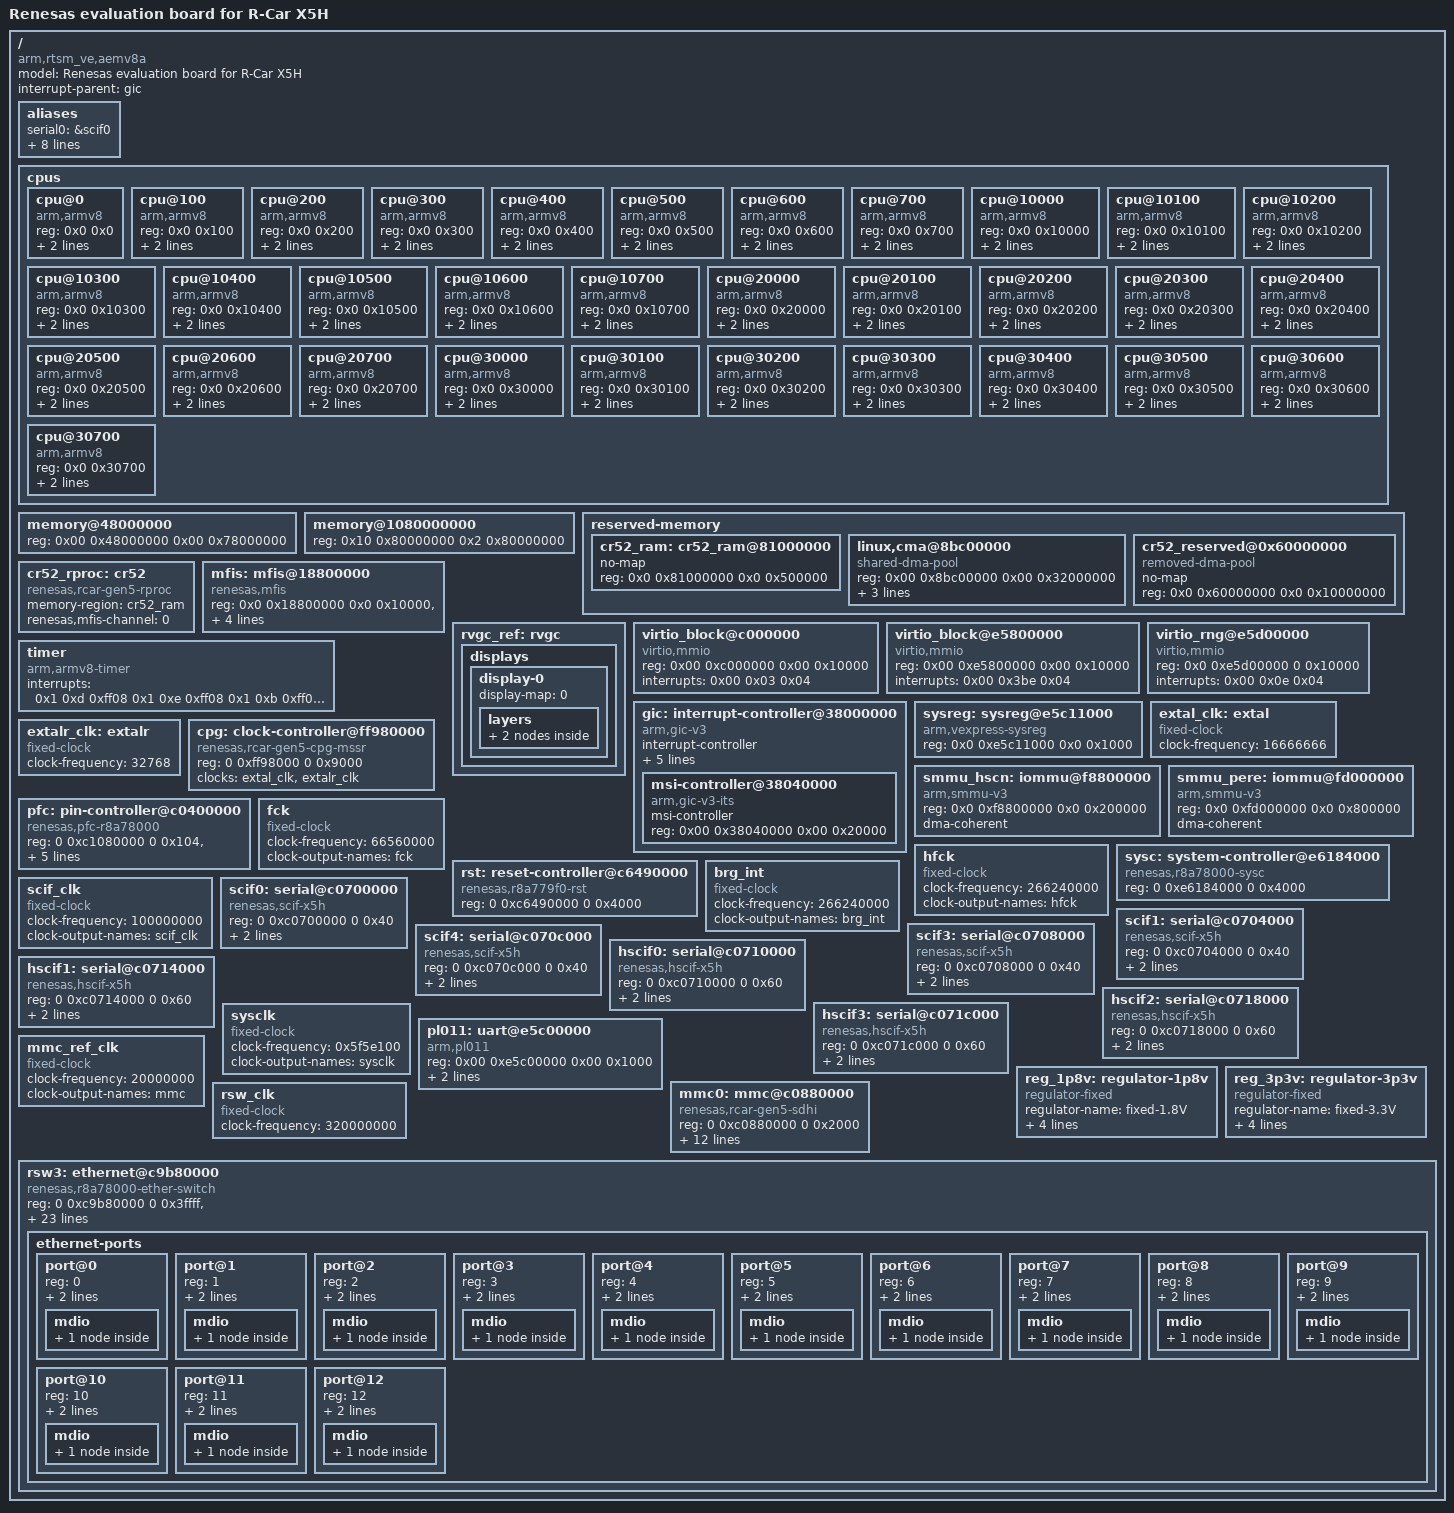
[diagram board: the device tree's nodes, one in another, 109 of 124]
/dts-v1/;

/ {
	model = "Renesas evaluation board for R-Car X5H";
	compatible = "arm,rtsm_ve,aemv8a", "arm,vexpress";
	#address-cells = <2>;
	#size-cells = <2>;

	interrupt-parent = <&gic>;

	aliases {
		serial0 = &scif0;
		serial1 = &scif1;
		serial2 = &scif3;
		serial3 = &scif4;
		serial4 = &hscif0;
		serial5 = &hscif1;
		serial6 = &hscif2;
		serial7 = &hscif3;
		serial8 = &pl011;
	};

	cpus {
		#address-cells = <2>;
		#size-cells = <0>;
		
		cpu@0 {
			device_type = "cpu";
			compatible = "arm,armv8";
			reg = <0x0 0x0>;
			enable-method = "spin-table";
			cpu-release-addr = <0x0 0x7ffff00>;
		};
		cpu@100 {
			device_type = "cpu";
			compatible = "arm,armv8";
			reg = <0x0 0x100>;
			enable-method = "spin-table";
			cpu-release-addr = <0x0 0x7ffff00>;
		};
		cpu@200 {
			device_type = "cpu";
			compatible = "arm,armv8";
			reg = <0x0 0x200>;
			enable-method = "spin-table";
			cpu-release-addr = <0x0 0x7ffff00>;
		};
		cpu@300 {
			device_type = "cpu";
			compatible = "arm,armv8";
			reg = <0x0 0x300>;
			enable-method = "spin-table";
			cpu-release-addr = <0x0 0x7ffff00>;
		};
		cpu@400 {
			device_type = "cpu";
			compatible = "arm,armv8";
			reg = <0x0 0x400>;
			enable-method = "spin-table";
			cpu-release-addr = <0x0 0x7ffff00>;
		};
		cpu@500 {
			device_type = "cpu";
			compatible = "arm,armv8";
			reg = <0x0 0x500>;
			enable-method = "spin-table";
			cpu-release-addr = <0x0 0x7ffff00>;
		};
		cpu@600 {
			device_type = "cpu";
			compatible = "arm,armv8";
			reg = <0x0 0x600>;
			enable-method = "spin-table";
			cpu-release-addr = <0x0 0x7ffff00>;
		};
		cpu@700 {
			device_type = "cpu";
			compatible = "arm,armv8";
			reg = <0x0 0x700>;
			enable-method = "spin-table";
			cpu-release-addr = <0x0 0x7ffff00>;
		};
		cpu@10000 {
			device_type = "cpu";
			compatible = "arm,armv8";
			reg = <0x0 0x10000>;
			enable-method = "spin-table";
			cpu-release-addr = <0x0 0x7ffff00>;
		};
		cpu@10100 {
			device_type = "cpu";
			compatible = "arm,armv8";
			reg = <0x0 0x10100>;
			enable-method = "spin-table";
			cpu-release-addr = <0x0 0x7ffff00>;
		};
		cpu@10200 {
			device_type = "cpu";
			compatible = "arm,armv8";
			reg = <0x0 0x10200>;
			enable-method = "spin-table";
			cpu-release-addr = <0x0 0x7ffff00>;
		};
		cpu@10300 {
			device_type = "cpu";
			compatible = "arm,armv8";
			reg = <0x0 0x10300>;
			enable-method = "spin-table";
			cpu-release-addr = <0x0 0x7ffff00>;
		};
		cpu@10400 {
			device_type = "cpu";
			compatible = "arm,armv8";
			reg = <0x0 0x10400>;
			enable-method = "spin-table";
			cpu-release-addr = <0x0 0x7ffff00>;
		};
		cpu@10500 {
			device_type = "cpu";
			compatible = "arm,armv8";
			reg = <0x0 0x10500>;
			enable-method = "spin-table";
			cpu-release-addr = <0x0 0x7ffff00>;
		};
		cpu@10600 {
			device_type = "cpu";
			compatible = "arm,armv8";
			reg = <0x0 0x10600>;
			enable-method = "spin-table";
			cpu-release-addr = <0x0 0x7ffff00>;
		};
		cpu@10700 {
			device_type = "cpu";
			compatible = "arm,armv8";
			reg = <0x0 0x10700>;
			enable-method = "spin-table";
			cpu-release-addr = <0x0 0x7ffff00>;
		};
		cpu@20000 {
			device_type = "cpu";
			compatible = "arm,armv8";
			reg = <0x0 0x20000>;
			enable-method = "spin-table";
			cpu-release-addr = <0x0 0x7ffff00>;
		};
		cpu@20100 {
			device_type = "cpu";
			compatible = "arm,armv8";
			reg = <0x0 0x20100>;
			enable-method = "spin-table";
			cpu-release-addr = <0x0 0x7ffff00>;
		};
		cpu@20200 {
			device_type = "cpu";
			compatible = "arm,armv8";
			reg = <0x0 0x20200>;
			enable-method = "spin-table";
			cpu-release-addr = <0x0 0x7ffff00>;
		};
		cpu@20300 {
			device_type = "cpu";
			compatible = "arm,armv8";
			reg = <0x0 0x20300>;
			enable-method = "spin-table";
			cpu-release-addr = <0x0 0x7ffff00>;
		};
		cpu@20400 {
			device_type = "cpu";
			compatible = "arm,armv8";
			reg = <0x0 0x20400>;
			enable-method = "spin-table";
			cpu-release-addr = <0x0 0x7ffff00>;
		};
		cpu@20500 {
			device_type = "cpu";
			compatible = "arm,armv8";
			reg = <0x0 0x20500>;
			enable-method = "spin-table";
			cpu-release-addr = <0x0 0x7ffff00>;
		};
		cpu@20600 {
			device_type = "cpu";
			compatible = "arm,armv8";
			reg = <0x0 0x20600>;
			enable-method = "spin-table";
			cpu-release-addr = <0x0 0x7ffff00>;
		};
		cpu@20700 {
			device_type = "cpu";
			compatible = "arm,armv8";
			reg = <0x0 0x20700>;
			enable-method = "spin-table";
			cpu-release-addr = <0x0 0x7ffff00>;
		};
		cpu@30000 {
			device_type = "cpu";
			compatible = "arm,armv8";
			reg = <0x0 0x30000>;
			enable-method = "spin-table";
			cpu-release-addr = <0x0 0x7ffff00>;
		};
		cpu@30100 {
			device_type = "cpu";
			compatible = "arm,armv8";
			reg = <0x0 0x30100>;
			enable-method = "spin-table";
			cpu-release-addr = <0x0 0x7ffff00>;
		};
		cpu@30200 {
			device_type = "cpu";
			compatible = "arm,armv8";
			reg = <0x0 0x30200>;
			enable-method = "spin-table";
			cpu-release-addr = <0x0 0x7ffff00>;
		};
		cpu@30300 {
			device_type = "cpu";
			compatible = "arm,armv8";
			reg = <0x0 0x30300>;
			enable-method = "spin-table";
			cpu-release-addr = <0x0 0x7ffff00>;
		};
		cpu@30400 {
			device_type = "cpu";
			compatible = "arm,armv8";
			reg = <0x0 0x30400>;
			enable-method = "spin-table";
			cpu-release-addr = <0x0 0x7ffff00>;
		};
		cpu@30500 {
			device_type = "cpu";
			compatible = "arm,armv8";
			reg = <0x0 0x30500>;
			enable-method = "spin-table";
			cpu-release-addr = <0x0 0x7ffff00>;
		};
		cpu@30600 {
			device_type = "cpu";
			compatible = "arm,armv8";
			reg = <0x0 0x30600>;
			enable-method = "spin-table";
			cpu-release-addr = <0x0 0x7ffff00>;
		};
		cpu@30700 {
			device_type = "cpu";
			compatible = "arm,armv8";
			reg = <0x0 0x30700>;
			enable-method = "spin-table";
			cpu-release-addr = <0x0 0x7ffff00>;
		};
	};

	memory@48000000 {
		device_type = "memory";
		reg = <0x00 0x48000000 0x00 0x78000000>;
	};

	memory@1080000000 {
		device_type = "memory";
		reg = <0x10 0x80000000 0x2 0x80000000>;
	};

	reserved-memory {
		#address-cells = <2>;
		#size-cells = <2>;
		ranges;
 
		cr52_ram: cr52_ram@81000000 {
			no-map;
			reg = <0x0 0x81000000 0x0 0x500000>;
		};

		linux,cma@8bc00000 {
			compatible = "shared-dma-pool";
			reg = <0x00 0x8bc00000 0x00 0x32000000>;
			linux;
			reusable;
			linux,cma-default;
		};

		cr52_reserved@0x60000000 {
			compatible = "removed-dma-pool";
			no-map;
			reg = <0x0 0x60000000 0x0 0x10000000>;
		};
	};

	cr52_rproc: cr52 {
		compatible = "renesas,rcar-gen5-rproc";
		memory-region = <&cr52_ram>;
		renesas,mfis-channel = <0>;
	};

	mfis: mfis@18800000 {
		compatible = "renesas,mfis";
		reg = <0x0 0x18800000 0x0 0x10000>, <0x0 0x189e0900 0x0 0x4>;
		reg-names = "io_base", "unlock_reg";
		interrupts = <0 101 4>, <0 103 4>, <0 105 4>, <0 107 4>, <0 109 4>, <0 111 4>, <0 113 4>, <0 115 4>;
		interrupt-names = "eicr0", "eicr1", "eicr2", "eicr3", "eicr4", "eicr5", "eicr6", "eicr7";
		renesas,mfis-channels = <0 1 2 3>;
		status = "okay";
	};

	rvgc_ref: rvgc {
		#address-cells = <2>;
		#size-cells = <2>;
		displays {
			display-0 {
				display-map = <0>;
				layers {
					primary{
						/* Position the layer */
						layer-map=<0x1>;
						size-w=<1920>;
						size-h=<1080>;
						pos-x=<0>;	
						pos-y=<0>;	
						pos-override;
 					};
					overlay-0 {
						layer-map = <0x2>;
						size-w = <1920>;
						size-h = <1080>;
						pos-x = <0>;
						pos-y = <0>;
					};								
				};
			};
		};
	};

	virtio_block@c000000 {
		compatible = "virtio,mmio";
		reg = <0x00 0xc000000 0x00 0x10000>;
		interrupts = <0x00 0x03 0x04>;
		status = "okay";
	};

	virtio_block@e5800000 {
		compatible = "virtio,mmio";
		reg = <0x00 0xe5800000 0x00 0x10000>;
		interrupts = <0x00 0x3be 0x04>;
		status = "okay";
	};

	virtio_rng@e5d00000 {
		compatible = "virtio,mmio";
		reg = <0x0 0xe5d00000 0 0x10000>;
		interrupts = <0x00 0x0e 0x04>;
	};

	timer {
		compatible = "arm,armv8-timer";
		interrupts = <0x1 0xd 0xff08 0x1 0xe 0xff08 0x1 0xb 0xff08 0x1 0xa 0xff08>;
	};

	gic: interrupt-controller@38000000 {
		compatible = "arm,gic-v3";
		#interrupt-cells = <0x03>;
		#address-cells = <0x02>;
		#size-cells = <0x02>;
		ranges;
		interrupt-controller;
		reg = <0x0 0x38000000 0x0 0x10000>, <0x0 0x38080000 0x0 0x4080000>, <0x0 0x0 0x0 0x2000>, <0x0 0x10000 0x0 0x2000>, <0x0 0x20000 0x0 0x2000>;
		interrupts = <0x01 0x09 0xff04>;
		phandle = <0x14>;

		msi-controller@38040000 {
			compatible = "arm,gic-v3-its";
			msi-controller;
			#msi-cells = <0x01>;
			reg = <0x00 0x38040000 0x00 0x20000>;
			phandle = <0x2f>;
		};
	};

	sysreg: sysreg@e5c11000 {
		compatible = "arm,vexpress-sysreg";
		reg = <0x0 0xe5c11000 0x0 0x1000>;
	};

	extal_clk: extal {
		compatible = "fixed-clock";
		#clock-cells = <0>;
		/* This value must be overridden by the board */
		clock-frequency = <16666666>;
	};
	
	extalr_clk: extalr {
		compatible = "fixed-clock";
		#clock-cells = <0>;
		/* This value must be overridden by the board */
		clock-frequency = <32768>;
	};
	
	cpg: clock-controller@ff980000 {
		compatible = "renesas,rcar-gen5-cpg-mssr";
		reg = <0 0xff98000 0 0x9000>;
		clocks = <&extal_clk>, <&extalr_clk>;
		clock-names = "extal", "extalr";
		#clock-cells = <2>;
		#power-domain-cells = <0>;
		#reset-cells = <1>;
	};
	
	smmu_hscn: iommu@f8800000 {
		compatible = "arm,smmu-v3";
		reg = <0x0 0xf8800000 0x0 0x200000>;
		#iommu-cells = <1>;
		dma-coherent;
	};

	smmu_pere: iommu@fd000000 {
		compatible = "arm,smmu-v3";
		reg = <0x0 0xfd000000 0x0 0x800000>;
		#iommu-cells = <1>;
		dma-coherent;
	};

	/* pfc_gen5.dts.txt */
	pfc: pin-controller@c0400000 {
		compatible = "renesas,pfc-r8a78000";
		reg = <0 0xc1080000 0 0x104>,
			  <0 0xc1080800 0 0x104>,
			  <0 0xc1081000 0 0x104>,
			  <0 0xc0800000 0 0x104>,
			  <0 0xc0800800 0 0x104>,
			  <0 0xc0400000 0 0x104>,
			  <0 0xc0400800 0 0x104>,
			  <0 0xc0401000 0 0x104>,
			  <0 0xc0401800 0 0x104>,
			  <0 0xc9b00000 0 0x104>,
			  <0 0xc9b00800 0 0x104>;
	};
	/* pfc_gen5.dts.txt end */

	fck: fck {
		compatible = "fixed-clock";
		#clock-cells = <0>;
		clock-frequency = <66560000>;
		clock-output-names = "fck";
	};
	
	hfck: hfck {
		compatible = "fixed-clock";
		#clock-cells = <0>;
		clock-frequency = <266240000>;
		clock-output-names = "hfck";
	};

	sysc: system-controller@e6184000 {
		compatible = "renesas,r8a78000-sysc";
		reg = <0 0xe6184000 0 0x4000>;
		#power-domain-cells = <1>;
	};

	rst: reset-controller@c6490000 {
		compatible = "renesas,r8a779f0-rst";
		reg = <0 0xc6490000 0 0x4000>;
	};
	
	brg_int: brg_int {
		compatible = "fixed-clock";
		#clock-cells = <0>;
		clock-frequency = <266240000>;
		clock-output-names = "brg_int";
	};
	
	scif_clk: scif_clk {
		compatible = "fixed-clock";
		#clock-cells = <0>;
		clock-frequency = <100000000>;
		clock-output-names = "scif_clk";
	};

	scif0: serial@c0700000 {
		compatible = "renesas,scif-x5h", "renesas,rcar-gen5-scif", "renesas,scif";
		reg = <0 0xc0700000 0 0x40>;
		interrupts = <0 433 4>;
		clocks = <&scif_clk>, <&scif_clk>, <&scif_clk>;
		clock-names = "fck", "brg_int", "scif_clk";
	};

	scif1: serial@c0704000 {
		compatible = "renesas,scif-x5h", "renesas,rcar-gen5-scif", "renesas,scif";
		reg = <0 0xc0704000 0 0x40>;
		interrupts = <0 433 4>;
		clocks = <&scif_clk>, <&scif_clk>, <&scif_clk>;
		clock-names = "fck", "brg_int", "scif_clk";
	};

	scif3: serial@c0708000 {
		compatible = "renesas,scif-x5h", "renesas,rcar-gen5-scif", "renesas,scif";
		reg = <0 0xc0708000 0 0x40>;
		interrupts = <0 433 4>;
		clocks = <&scif_clk>, <&scif_clk>, <&scif_clk>;
		clock-names = "fck", "brg_int", "scif_clk";
	};

	scif4: serial@c070c000 {
		compatible = "renesas,scif-x5h", "renesas,rcar-gen5-scif", "renesas,scif";
		reg = <0 0xc070c000 0 0x40>;
		interrupts = <0 433 4>;
		clocks = <&scif_clk>, <&scif_clk>, <&scif_clk>;
		clock-names = "fck", "brg_int", "scif_clk";
	};

	hscif0: serial@c0710000 {
		compatible = "renesas,hscif-x5h", "renesas,rcar-gen5-hscif", "renesas,hscif";
		reg = <0 0xc0710000 0 0x60>;
		interrupts = <0 434 4>;
		clocks = <&scif_clk>, <&scif_clk>, <&scif_clk>;
		clock-names = "fck", "brg_int", "scif_clk";
	};

	hscif1: serial@c0714000 {
		compatible = "renesas,hscif-x5h", "renesas,rcar-gen5-hscif", "renesas,hscif";
		reg = <0 0xc0714000 0 0x60>;
		interrupts = <0 434 4>;
		clocks = <&scif_clk>, <&scif_clk>, <&scif_clk>;
		clock-names = "fck", "brg_int", "scif_clk";
	};

	hscif2: serial@c0718000 {
		compatible = "renesas,hscif-x5h", "renesas,rcar-gen5-hscif", "renesas,hscif";
		reg = <0 0xc0718000 0 0x60>;
		interrupts = <0 434 4>;
		clocks = <&scif_clk>, <&scif_clk>, <&scif_clk>;
		clock-names = "fck", "brg_int", "scif_clk";
	};

	hscif3: serial@c071c000 {
		compatible = "renesas,hscif-x5h", "renesas,rcar-gen5-hscif", "renesas,hscif";
		reg = <0 0xc071c000 0 0x60>;
		interrupts = <0 434 4>;
		clocks = <&scif_clk>, <&scif_clk>, <&scif_clk>;
		clock-names = "fck", "brg_int", "scif_clk";
	};

	sysclk: sysclk {
		compatible = "fixed-clock";
		#clock-cells = <0x00>;
		clock-frequency = <0x5f5e100>;
		clock-output-names = "sysclk";
	};

	pl011: uart@e5c00000 {
		compatible = "arm,pl011", "arm,primecell";
		reg = <0x00 0xe5c00000 0x00 0x1000>;
		interrupts = <0 13 4>;
		clock-names = "uartclk", "apb_pclk";
		clocks = <&sysclk>, <&sysclk>;
	};

	reg_1p8v: regulator-1p8v {
		compatible = "regulator-fixed";
		regulator-name = "fixed-1.8V";
		regulator-min-microvolt = <1800000>;
		regulator-max-microvolt = <1800000>;
		regulator-boot-on;
		regulator-always-on;
	};

	reg_3p3v: regulator-3p3v {
		compatible = "regulator-fixed";
		regulator-name = "fixed-3.3V";
		regulator-min-microvolt = <3300000>;
		regulator-max-microvolt = <3300000>;
		regulator-boot-on;
		regulator-always-on;
	};

	mmc_ref_clk: mmc_ref_clk {
		compatible = "fixed-clock";
		#clock-cells = <0>;
		clock-frequency = <20000000>;
		clock-output-names = "mmc";
	};

	mmc0: mmc@c0880000 {
		compatible = "renesas,rcar-gen5-sdhi";
		reg = <0 0xc0880000 0 0x2000>;
		interrupts = <0 894 4>;
		clocks = <&mmc_ref_clk>;
		max-frequency = <200000000>;
		vmmc-supply = <&reg_3p3v>;
		vqmmc-supply = <&reg_1p8v>;
		mmc-hs200-1_8v;
		mmc-hs400-1_8v;
		bus-width = <8>;
		no-sd;
		no-sdio;
		non-removable;
		full-pwr-cycle-in-suspend;
	};

	rsw_clk: rsw_clk {
		compatible = "fixed-clock";
		clock-frequency = <320000000>;
		#clock-cells = <0>;
	};

	rsw3: ethernet@c9b80000 {
		compatible = "renesas,r8a78000-ether-switch",
					"renesas,etherswitch";
		reg =	<0 0xc9b80000 0 0x3ffff>,
			<0 0xc9c89000 0 0x7ff>,
			<0 0xc9c50000 0 0x3ff>;
		reg-names = "secure_base", "gptp", "xpsc";
		interrupts = <0 799 4>, <0 800 4>,
			   <0 801 4>, <0 802 4>,
			   <0 803 4>, <0 804 4>,
			   <0 805 4>, <0 806 4>,
			   <0 807 4>, <0 808 4>,
			   <0 809 4>, <0 810 4>,
			   <0 811 4>, <0 812 4>,
			   <0 813 4>, <0 814 4>,
			   <0 815 4>, <0 816 4>,
			   <0 817 4>, <0 818 4>,
			   <0 826 4>, <0 820 4>,
			   <0 821 4>, <0 822 4>,
			   <0 823 4>, <0 824 4>,
			   <0 825 4>, <0 826 4>, // gwca1_gwdis 825
			   <0 827 4>, <0 828 4>,
			   <0 829 4>, <0 830 4>,
			   <0 831 4>, <0 832 4>,
			   <0 833 4>, <0 834 4>,
			   <0 835 4>, <0 836 4>,
			   <0 837 4>, <0 838 4>,
			   <0 839 4>, <0 840 4>,
			   <0 841 4>, <0 842 4>,
			   <0 843 4>, <0 844 4>,
			   <0 845 4>, <0 846 4>,
			   <0 847 4>, <0 848 4>,
			   <0 849 4>, <0 850 4>,
			   <0 851 4>, <0 852 4>,
			   <0 853 4>, <0 854 4>,
			   <0 855 4>, <0 856 4>,
			   <0 857 4>, <0 858 4>,
			   <0 859 4>, <0 860 4>,
			   <0 861 4>, <0 862 4>,
			   <0 863 4>, <0 864 4>,
			   <0 865 4>, <0 866 4>,
			   <0 867 4>, <0 868 4>,
			   <0 869 4>, <0 870 4>,
			   <0 871 4>, <0 872 4>,
			   <0 873 4>, <0 874 4>,
			   <0 875 4>, <0 876 4>,
			   <0 877 4>, <0 878 4>,
			   <0 879 4>, <0 880 4>,
			   <0 881 4>, <0 882 4>,
			   <0 883 4>, <0 884 4>,
			   <0 885 4>, <0 886 4>,
			   <0 887 4>, <0 888 4>,
			   <0 889 4>, <0 890 4>,
			   <0 891 4>, <0 892 4>,
			   <0 893 4>;
		interrupt-names = "race_wrap_mfwd_int", "race_wrap_race_int",
			"race_wrap_coma_int", "race_wrap_gwca0_int",
			"race_wrap_gwca1_int", "race_wrap_etha0_int",
			"race_wrap_etha1_int", "race_wrap_etha2_int",
			"race_wrap_etha3_int", "race_wrap_etha4_int",
			"race_wrap_etha5_int", "race_wrap_etha6_int",
			"race_wrap_etha7_int", "race_wrap_etha8_int",
			"race_wrap_etha9_int", "race_wrap_etha10_int",
			"race_wrap_etha11_int", "race_wrap_etha12_int",
			"race_wrap_gwca0_gwdis_int0", "race_wrap_gwca0_gwdis_int1",
			"race_wrap_gwca0_gwdis_int2", "race_wrap_gwca0_gwdis_int3",
			"race_wrap_gwca0_gwdis_int4", "race_wrap_gwca0_gwdis_int5",
			"race_wrap_gwca0_gwdis_int6", "race_wrap_gwca0_gwdis_int7",
			"gwca1_gwdis0", "gwca1_gwdis1", /// 825
			"gwca1_gwdis2", "gwca1_gwdis3",
			"gwca1_gwdis4", "gwca1_gwdis5",
			"gwca1_gwdis6", "gwca1_gwdis7",
			"race_wrap_gwca0_gwtsdis_int0", "race_wrap_gwca0_gwtsdis_int1",
			"race_wrap_gwca1_gwtsdis_int0", "race_wrap_gwca1_gwtsdis_int1",
			"race_wrap_gptp_int", "tes0_status_int",
			"tes0_tx_int", "tes0_rx_int",
			"tes0_ts_int", "tes0_error_int",
			"tes1_status_int", "tes1_tx_int",
			"tes1_rx_int", "tes1_ts_int",
			"tes1_error_int", "tes2_status_int",
			"tes2_tx_int", "tes2_rx_int",
			"tes2_ts_int", "tes2_error_int",
			"tes3_status_int", "tes3_tx_int",
			"tes3_rx_int", "tes3_ts_int",
			"tes3_error_int", "tes4_status_int",
			"tes4_tx_int", "tes4_rx_int",
			"tes4_ts_int", "tes4_error_int",
			"tes5_status_int", "tes5_tx_int",
			"tes5_rx_int", "tes5_ts_int",
			"tes5_error_int", "tes6_status_int",
			"tes6_tx_int", "tes6_rx_int",
			"tes6_ts_int", "tes6_error_int",
			"tes7_status_int", "tes7_tx_int",
			"tes7_rx_int", "tes7_ts_int",
			"tes7_error_int", "tes0_gptp_int",
			"tes1_gptp_int", "tes2_gptp_int",
			"tes3_gptp_int", "tes4_gptp_int",
			"tes5_gptp_int", "tes6_gptp_int",
			"tes7_gptp_int", "race_wrap_msc0_error_int",
			"race_wrap_msc1_error_int", "race_wrap_msc2_error_int",
			"race_wrap_msc3_error_int", "race_wrap_msc4_error_int",
			"race_wrap_msc5_error_int", "race_wrap_msc6_error_int",
			"race_wrap_msc7_error_int";
		#address-cells = <1>;
		#size-cells = <0>;
		clocks = <&rsw_clk>, <&rsw_clk>;
		clock-names = "rsw2", "eth-phy";
		vpf_mode;
		status = "okay";

		ethernet-ports {
			#address-cells = <1>;
			#size-cells = <0>;

			port@0 {
				reg = <0>;
				phy-handle = <&u101>;
				phy-mode = "sgmii";

				mdio {
					#address-cells = <1>;
					#size-cells = <0>;

					u101: ethernet-phy@0 {
						reg = <0>;
					};
				};
			};
			port@1 {
				reg = <1>;
				phy-handle = <&u102>;
				phy-mode = "sgmii";

				mdio {
					#address-cells = <1>;
					#size-cells = <0>;

					u102: ethernet-phy@1 {
						reg = <1>;
					};
				};
			};
			port@2 {
				reg = <2>;
				phy-handle = <&u103>;
				phy-mode = "sgmii";

				mdio {
					#address-cells = <1>;
					#size-cells = <0>;

					u103: ethernet-phy@2 {
						reg = <2>;
					};
				};
			};
			port@3 {
				reg = <3>;
				phy-handle = <&u104>;
				phy-mode = "sgmii";

				mdio {
					#address-cells = <1>;
					#size-cells = <0>;

					u104: ethernet-phy@3 {
						reg = <3>;
					};
				};
			};
			port@4 {
				reg = <4>;
				phy-handle = <&u105>;
				phy-mode = "sgmii";

				mdio {
					#address-cells = <1>;
					#size-cells = <0>;

					u105: ethernet-phy@4 {
						reg = <4>;
					};
				};
			};
			port@5 {
				reg = <5>;
				phy-handle = <&u106>;
				phy-mode = "sgmii";

				mdio {
					#address-cells = <1>;
					#size-cells = <0>;

					u106: ethernet-phy@5 {
						reg = <5>;
					};
				};
			};
			port@6 {
				reg = <6>;
				phy-handle = <&u107>;
				phy-mode = "sgmii";

				mdio {
					#address-cells = <1>;
					#size-cells = <0>;

					u107: ethernet-phy@6 {
						reg = <6>;
					};
				};
			};
			port@7 {
				reg = <7>;
				phy-handle = <&u108>;
				phy-mode = "sgmii";

				mdio {
					#address-cells = <1>;
					#size-cells = <0>;

					u108: ethernet-phy@7 {
						reg = <7>;
					};
				};
			};
			port@8 {
				reg = <8>;
				phy-handle = <&u109>;
				phy-mode = "sgmii";

				mdio {
					#address-cells = <1>;
					#size-cells = <0>;

					u109: ethernet-phy@8 {
						reg = <8>;
					};
				};
			};
			port@9 {
				reg = <9>;
				phy-handle = <&u110>;
				phy-mode = "sgmii";

				mdio {
					#address-cells = <1>;
					#size-cells = <0>;

					u110: ethernet-phy@9 {
						reg = <9>;
					};
				};
			};
			port@10 {
				reg = <10>;
				phy-handle = <&u111>;
				phy-mode = "sgmii";

				mdio {
					#address-cells = <1>;
					#size-cells = <0>;

					u111: ethernet-phy@10 {
						reg = <10>;
					};
				};
			};
			port@11 {
				reg = <11>;
				phy-handle = <&u112>;
				phy-mode = "sgmii";

				mdio {
					#address-cells = <1>;
					#size-cells = <0>;

					u112: ethernet-phy@11 {
						reg = <11>;
					};
				};
			};
			port@12 {
				reg = <12>;
				phy-handle = <&u113>;
				phy-mode = "sgmii";

				mdio {
					#address-cells = <1>;
					#size-cells = <0>;

					u113: ethernet-phy@12 {
						reg = <12>;
					};
				};
			};
		};
	};
};
